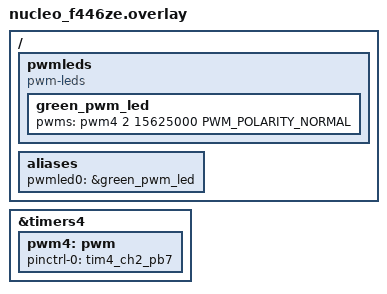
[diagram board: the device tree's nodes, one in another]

/* SPDX-License-Identifier: Apache-2.0 */

/ {
	/*servo: servo {
		compatible = "pwm-servo";
		pwms = <&sw_pwm 0 PWM_MSEC(20) PWM_POLARITY_NORMAL>;
		min-pulse = <PWM_USEC(700)>;
		max-pulse = <PWM_USEC(2500)>;
	};*/
    
    pwmleds {
        compatible = "pwm-leds";
        green_pwm_led: green_pwm_led {
            pwms = <&pwm4 2 15625000 PWM_POLARITY_NORMAL>;
        };
    };

    aliases {
        pwmled0 = &green_pwm_led;
    };

};


&timers4 {
	status = "okay";

	pwm4: pwm {
		status = "okay";
		pinctrl-0 = <&tim4_ch2_pb7>;
		pinctrl-names = "default";
	};
};
